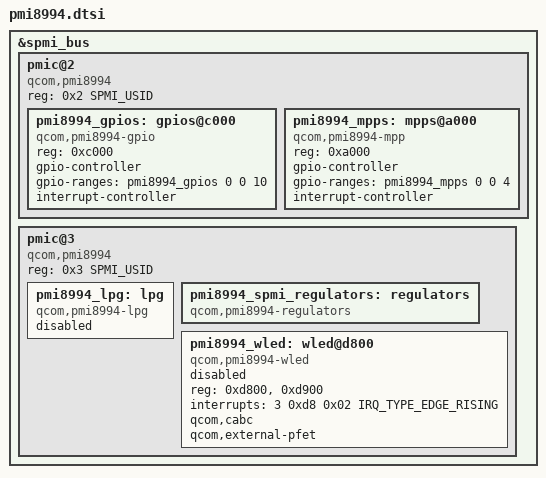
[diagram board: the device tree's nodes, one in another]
// SPDX-License-Identifier: GPL-2.0
#include <dt-bindings/interrupt-controller/irq.h>
#include <dt-bindings/spmi/spmi.h>

&spmi_bus {

	pmic@2 {
		compatible = "qcom,pmi8994", "qcom,spmi-pmic";
		reg = <0x2 SPMI_USID>;
		#address-cells = <1>;
		#size-cells = <0>;

		pmi8994_gpios: gpios@c000 {
			compatible = "qcom,pmi8994-gpio", "qcom,spmi-gpio";
			reg = <0xc000>;
			gpio-controller;
			gpio-ranges = <&pmi8994_gpios 0 0 10>;
			#gpio-cells = <2>;
			interrupt-controller;
			#interrupt-cells = <2>;
		};

		pmi8994_mpps: mpps@a000 {
			compatible = "qcom,pmi8994-mpp";
			reg = <0xa000>;
			gpio-controller;
			gpio-ranges = <&pmi8994_mpps 0 0 4>;
			#gpio-cells = <2>;
			interrupt-controller;
			#interrupt-cells = <2>;
		};
	};

	pmic@3 {
		compatible = "qcom,pmi8994", "qcom,spmi-pmic";
		reg = <0x3 SPMI_USID>;
		#address-cells = <1>;
		#size-cells = <0>;

		pmi8994_lpg: lpg {
			compatible = "qcom,pmi8994-lpg";

			#address-cells = <1>;
			#size-cells = <0>;
			#pwm-cells = <2>;

			status = "disabled";
		};

		pmi8994_spmi_regulators: regulators {
			compatible = "qcom,pmi8994-regulators";
			#address-cells = <1>;
			#size-cells = <1>;
		};

		pmi8994_wled: wled@d800 {
			compatible = "qcom,pmi8994-wled";
			reg = <0xd800>, <0xd900>;
			interrupts = <3 0xd8 0x02 IRQ_TYPE_EDGE_RISING>;
			interrupt-names = "short";
			qcom,cabc;
			qcom,external-pfet;
			status = "disabled";
		};
	};
};
